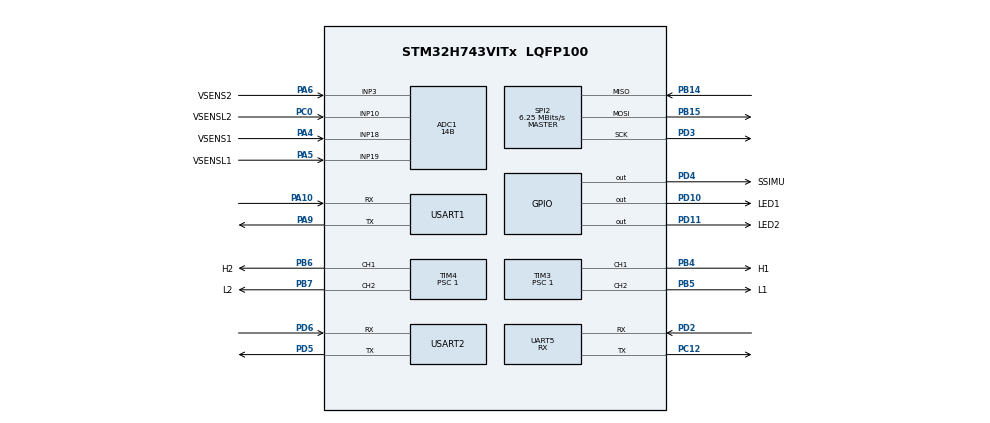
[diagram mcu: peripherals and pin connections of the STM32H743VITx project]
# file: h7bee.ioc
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ADC1.ContinuousConvMode=ENABLE
ADC1.ConversionDataManagement=ADC_CONVERSIONDATA_DR
ADC1.EnableInjectedConversion=ENABLE
ADC1.EnableRegularConversion=DISABLE
ADC1.InjNumberOfConversion=4
ADC1.InjectedChannel-5\#ChannelInjectedConversion=ADC_CHANNEL_3
ADC1.InjectedChannel-6\#ChannelInjectedConversion=ADC_CHANNEL_10
ADC1.InjectedChannel-7\#ChannelInjectedConversion=ADC_CHANNEL_18
ADC1.InjectedChannel-8\#ChannelInjectedConversion=ADC_CHANNEL_19
ADC1.InjectedOffsetNumber-5\#ChannelInjectedConversion=ADC_OFFSET_NONE
ADC1.InjectedOffsetNumber-6\#ChannelInjectedConversion=ADC_OFFSET_NONE
ADC1.InjectedOffsetNumber-7\#ChannelInjectedConversion=ADC_OFFSET_NONE
ADC1.InjectedOffsetNumber-8\#ChannelInjectedConversion=ADC_OFFSET_NONE
ADC1.InjectedRank-5\#ChannelInjectedConversion=1
ADC1.InjectedRank-6\#ChannelInjectedConversion=2
ADC1.InjectedRank-7\#ChannelInjectedConversion=3
ADC1.InjectedRank-8\#ChannelInjectedConversion=4
ADC1.InjectedSamplingTime-5\#ChannelInjectedConversion=ADC_SAMPLETIME_16CYCLES_5
ADC1.InjectedSamplingTime-6\#ChannelInjectedConversion=ADC_SAMPLETIME_1CYCLE_5
ADC1.InjectedSamplingTime-7\#ChannelInjectedConversion=ADC_SAMPLETIME_1CYCLE_5
ADC1.InjectedSamplingTime-8\#ChannelInjectedConversion=ADC_SAMPLETIME_1CYCLE_5
ADC1.Overrun=ADC_OVR_DATA_OVERWRITTEN
ADC1.Resolution=ADC_RESOLUTION_14B
ADC1.injectedQueueMode=DISABLE
ADC1.master=1
CORTEX_M7.CPU_DCache=Enabled
CORTEX_M7.CPU_ICache=Enabled
CORTEX_M7.MPU_Control=MPU_PRIVILEGED_DEFAULT
FREERTOS.MEMORY_ALLOCATION=0
FREERTOS.Tasks01=heartbeatTask,-2,128,startHeartbeatTask,As weak,NULL,Dynamic,NULL,NULL;ImuTask,0,1024,startImuTask,As external,NULL,Dynamic,NULL,NULL;printfTask,-2,1024,startPrintfTask,As external,NULL,Dynamic,NULL,NULL
Mcu.Family=STM32H7
Mcu.Name=STM32H743VITx
Mcu.Package=LQFP100
NVIC.PriorityGroup=NVIC_PRIORITYGROUP_4
NVIC.TIM3_IRQn=true\:2\:0\:true\:false\:true\:false\:true\:true
NVIC.TIM6_DAC_IRQn=true\:1\:0\:true\:false\:true\:false\:true\:true
NVIC.TIM7_IRQn=true\:0\:0\:false\:false\:true\:false\:false\:true
NVIC.TimeBase=TIM7_IRQn
NVIC.TimeBaseIP=TIM7
NVIC.USART1_IRQn=true\:5\:0\:false\:false\:true\:true\:true\:true
PA10.Mode=Asynchronous
PA10.Signal=USART1_RX
PA4.GPIO_Label=VSENS1
PA4.Signal=ADCx_INP18
PA5.GPIO_Label=VSENSL1
PA5.Signal=ADCx_INP19
PA6.GPIO_Label=VSENS2
PA6.Signal=ADCx_INP3
PA9.Mode=Asynchronous
PA9.Signal=USART1_TX
PB14.Mode=Full_Duplex_Master
PB14.Signal=SPI2_MISO
PB15.Mode=Full_Duplex_Master
PB15.Signal=SPI2_MOSI
PB4\ (NJTRST).GPIO_Label=H1
PB4\ (NJTRST).GPIO_Speed=GPIO_SPEED_FREQ_VERY_HIGH
PB4\ (NJTRST).Signal=S_TIM3_CH1
PB5.GPIO_Label=L1
PB5.GPIO_Speed=GPIO_SPEED_FREQ_VERY_HIGH
PB5.Signal=S_TIM3_CH2
PB6.GPIO_Label=H2
PB6.GPIO_Speed=GPIO_SPEED_FREQ_VERY_HIGH
PB6.Signal=S_TIM4_CH1
PB7.GPIO_Label=L2
PB7.GPIO_Speed=GPIO_SPEED_FREQ_VERY_HIGH
PB7.Signal=S_TIM4_CH2
PC0.GPIO_Label=VSENSL2
PC0.Signal=ADCx_INP10
PC12.Mode=Asynchronous
PC12.Signal=UART5_TX
PD10.GPIO_Label=LED1
PD10.GPIO_ModeDefaultOutputPP=GPIO_MODE_OUTPUT_PP
PD10.GPIO_PuPd=GPIO_NOPULL
PD10.GPIO_Speed=GPIO_SPEED_FREQ_LOW
PD10.PinState=GPIO_PIN_SET
PD10.Signal=GPIO_Output
PD11.GPIO_Label=LED2
PD11.GPIO_ModeDefaultOutputPP=GPIO_MODE_OUTPUT_PP
PD11.GPIO_PuPd=GPIO_NOPULL
PD11.GPIO_Speed=GPIO_SPEED_FREQ_LOW
PD11.PinState=GPIO_PIN_SET
PD11.Signal=GPIO_Output
PD2.Mode=Asynchronous
PD2.Signal=UART5_RX
PD3.Mode=Full_Duplex_Master
PD3.Signal=SPI2_SCK
PD4.GPIO_Label=SSIMU
PD4.GPIO_ModeDefaultOutputPP=GPIO_MODE_OUTPUT_PP
PD4.GPIO_PuPd=GPIO_NOPULL
PD4.GPIO_Speed=GPIO_SPEED_FREQ_LOW
PD4.PinState=GPIO_PIN_SET
PD4.Signal=GPIO_Output
PD5.Mode=Asynchronous
PD5.Signal=USART2_TX
PD6.Mode=Asynchronous
PD6.Signal=USART2_RX
PH0-OSC_IN\ (PH0).Mode=HSE-External-Clock-Source
PH0-OSC_IN\ (PH0).Signal=RCC_OSC_IN
PH1-OSC_OUT\ (PH1).Mode=HSE-External-Clock-Source
PH1-OSC_OUT\ (PH1).Signal=RCC_OSC_OUT
ProjectManager.HeapSize=0x200
ProjectManager.StackSize=0x400
ProjectManager.TargetToolchain=Makefile
RCC.ADCFreq_Value=76000000
RCC.APB1Freq_Value=100000000
RCC.APB2Freq_Value=100000000
RCC.APB3Freq_Value=100000000
RCC.APB4Freq_Value=100000000
RCC.CKPERSourceSelection=RCC_CLKPSOURCE_HSE
RCC.CortexFreq_Value=400000000
RCC.D1PPRE=RCC_APB3_DIV2
RCC.D2PPRE1=RCC_APB1_DIV2
RCC.D2PPRE2=RCC_APB2_DIV2
RCC.D3PPRE=RCC_APB4_DIV2
RCC.DIVM1=1
RCC.DIVM2=1
RCC.DIVN1=100
RCC.DIVN2=19
RCC.HCLKFreq_Value=200000000
RCC.HPRE=RCC_HCLK_DIV2
RCC.HSE_VALUE=8000000
RCC.PLL2FRACN=0
RCC.PLL3FRACN=0
RCC.PLLFRACN=0
RCC.PLLSourceVirtual=RCC_PLLSOURCE_HSE
RCC.SYSCLKFreq_VALUE=400000000
RCC.SYSCLKSource=RCC_SYSCLKSOURCE_PLLCLK
RCC.USBFreq_Value=400000000
SH.ADCx_INP10.0=ADC1_INP10,IN10-Single-Ended
SH.ADCx_INP18.0=ADC1_INP18,IN18-Single-Ended
SH.ADCx_INP19.0=ADC1_INP19,IN19-Single-Ended
SH.ADCx_INP3.0=ADC1_INP3,IN3-Single-Ended
SH.S_TIM3_CH1.0=TIM3_CH1,PWM Generation1 CH1
SH.S_TIM3_CH2.0=TIM3_CH2,PWM Generation2 CH2
SH.S_TIM4_CH1.0=TIM4_CH1,PWM Generation1 CH1
SH.S_TIM4_CH2.0=TIM4_CH2,PWM Generation2 CH2
SPI2.BaudRatePrescaler=SPI_BAUDRATEPRESCALER_64
SPI2.CLKPhase=SPI_PHASE_1EDGE
SPI2.CalculateBaudRate=6.25 MBits/s
SPI2.DataSize=SPI_DATASIZE_8BIT
SPI2.Direction=SPI_DIRECTION_2LINES
SPI2.Mode=SPI_MODE_MASTER
SPI2.NSSPMode=SPI_NSS_PULSE_DISABLE
SPI2.VirtualType=VM_MASTER
TIM3.Channel-PWM\ Generation1\ CH1=TIM_CHANNEL_1
TIM3.Channel-PWM\ Generation2\ CH2=TIM_CHANNEL_2
TIM3.Period=9999
TIM3.Prescaler=1
TIM3.Pulse-PWM\ Generation1\ CH1=0
TIM3.Pulse-PWM\ Generation2\ CH2=0
TIM4.Channel-PWM\ Generation1\ CH1=TIM_CHANNEL_1
TIM4.Channel-PWM\ Generation2\ CH2=TIM_CHANNEL_2
TIM4.Period=9999
TIM4.Prescaler=1
TIM6.Period=999
TIM6.Prescaler=199
UART5.Mode=MODE_RX
USART1.VirtualMode-Asynchronous=VM_ASYNC
USART2.DataInvertParam=ADVFEATURE_DATAINV_ENABLE
USART2.RxPinLevelInvertParam=ADVFEATURE_RXINV_DISABLE
USART2.TxPinLevelInvertParam=ADVFEATURE_TXINV_DISABLE
USART2.VirtualMode-Asynchronous=VM_ASYNC
VP_FREERTOS_VS_CMSIS_V1.Mode=CMSIS_V1
VP_SYS_VS_tim7.Mode=TIM7
VP_TIM6_VS_ClockSourceINT.Mode=Enable_Timer
board=custom

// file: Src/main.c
/* USER CODE BEGIN Header */
/**
  ******************************************************************************
  * @file           : main.c
  * @brief          : Main program body
  ******************************************************************************
  * @attention
  *
  * <h2><center>&copy; Copyright (c) 2019 STMicroelectronics.
  * All rights reserved.</center></h2>
  *
  * This software component is licensed by ST under Ultimate Liberty license
  * SLA0044, the "License"; You may not use this file except in compliance with
  * the License. You may obtain a copy of the License at:
  *                             www.st.com/SLA0044
  *
  ******************************************************************************
  */
/* USER CODE END Header */

#include "main.h"
#include "cmsis_os.h"

ADC_HandleTypeDef hadc1;

SPI_HandleTypeDef hspi2;

TIM_HandleTypeDef htim3;
TIM_HandleTypeDef htim4;
TIM_HandleTypeDef htim6;

UART_HandleTypeDef huart5;
UART_HandleTypeDef huart1;
UART_HandleTypeDef huart2;

osThreadId heartbeatTaskHandle;
osThreadId ImuTaskHandle;
osThreadId printfTaskHandle;
/* USER CODE BEGIN PV */
// // adc_results_mem symbol is hardcoded in linker script so don't change it without updating it there
// #define RAM_D2 __attribute__((section(".d2ram")))
// volatile RAM_D2 uint32_t adc_results_mem[4];
/* USER CODE END PV */

void SystemClock_Config(void);
static void MPU_Config(void);
static void MX_GPIO_Init(void);
static void MX_SPI2_Init(void);
static void MX_UART5_Init(void);
static void MX_USART1_UART_Init(void);
static void MX_USART2_UART_Init(void);
static void MX_ADC1_Init(void);
static void MX_TIM3_Init(void);
static void MX_TIM4_Init(void);
static void MX_TIM6_Init(void);
void startHeartbeatTask(void const * argument);
extern void startImuTask(void const * argument);
extern void startPrintfTask(void const * argument);

int main(void)
{

  /* MPU Configuration--------------------------------------------------------*/
  MPU_Config();

  /* Enable I-Cache---------------------------------------------------------*/
  SCB_EnableICache();

  /* Enable D-Cache---------------------------------------------------------*/
  SCB_EnableDCache();

  /* MCU Configuration--------------------------------------------------------*/

  /* Reset of all peripherals, Initializes the Flash interface and the Systick. */
  HAL_Init();

  /* Configure the system clock */
  SystemClock_Config();

  /* Initialize all configured peripherals */
  MX_GPIO_Init();
  MX_SPI2_Init();
  MX_UART5_Init();
  MX_USART1_UART_Init();
  MX_USART2_UART_Init();
  MX_ADC1_Init();
  MX_TIM3_Init();
  MX_TIM4_Init();
  MX_TIM6_Init();
  /* USER CODE BEGIN 2 */

  // Start all the things that need to be started

  // System clock
  HAL_TIM_Base_Start(&htim6);
  HAL_TIM_Base_Start_IT(&htim6);

  // Drive PWM
  HAL_TIM_Base_Start(&htim3);
  HAL_TIM_PWM_Start(&htim3, TIM_CHANNEL_1);
  HAL_TIM_PWM_Start(&htim3, TIM_CHANNEL_2);
  HAL_TIM_Base_Start(&htim4);
  HAL_TIM_PWM_Start(&htim4, TIM_CHANNEL_1);
  HAL_TIM_PWM_Start(&htim4, TIM_CHANNEL_2);

  // ADC
  // for (int i = 0; i < 4; ++i)
  //   adc_results_mem[i] = 0;
  // HAL_ADC_Start_DMA(&hadc1, (uint32_t *)adc_results_mem, 4); // returns HAL_OK
  // HAL_ADC_Start(&hadc1);
  HAL_ADCEx_InjectedStart(&hadc1);

  // Flap task timebase (timer interrupt)
  HAL_TIM_Base_Start_IT(&htim3);

  /* USER CODE END 2 */

  /* Create the thread(s) */
  /* definition and creation of heartbeatTask */
  osThreadDef(heartbeatTask, startHeartbeatTask, osPriorityLow, 0, 128);
  heartbeatTaskHandle = osThreadCreate(osThread(heartbeatTask), NULL);

  /* definition and creation of ImuTask */
  osThreadDef(ImuTask, startImuTask, osPriorityNormal, 0, 1024);
  ImuTaskHandle = osThreadCreate(osThread(ImuTask), NULL);

  /* definition and creation of printfTask */
  osThreadDef(printfTask, startPrintfTask, osPriorityLow, 0, 1024);
  printfTaskHandle = osThreadCreate(osThread(printfTask), NULL);

  /* Start scheduler */
  osKernelStart();

  /* We should never get here as control is now taken by the scheduler */

  /* Infinite loop */
  while (1)
  {

  }
}

void SystemClock_Config(void)
{
  RCC_OscInitTypeDef RCC_OscInitStruct = {0};
  RCC_ClkInitTypeDef RCC_ClkInitStruct = {0};
  RCC_PeriphCLKInitTypeDef PeriphClkInitStruct = {0};

  /** Supply configuration update enable
  */
  HAL_PWREx_ConfigSupply(PWR_LDO_SUPPLY);
  /** Configure the main internal regulator output voltage
  */
  __HAL_PWR_VOLTAGESCALING_CONFIG(PWR_REGULATOR_VOLTAGE_SCALE1);

  while(!__HAL_PWR_GET_FLAG(PWR_FLAG_VOSRDY)) {}
  /** Macro to configure the PLL clock source
  */
  __HAL_RCC_PLL_PLLSOURCE_CONFIG(RCC_PLLSOURCE_HSE);
  /** Initializes the CPU, AHB and APB busses clocks
  */
  RCC_OscInitStruct.OscillatorType = RCC_OSCILLATORTYPE_HSE;
  RCC_OscInitStruct.HSEState = RCC_HSE_BYPASS;
  RCC_OscInitStruct.PLL.PLLState = RCC_PLL_ON;
  RCC_OscInitStruct.PLL.PLLSource = RCC_PLLSOURCE_HSE;
  RCC_OscInitStruct.PLL.PLLM = 1;
  RCC_OscInitStruct.PLL.PLLN = 100;
  RCC_OscInitStruct.PLL.PLLP = 2;
  RCC_OscInitStruct.PLL.PLLQ = 2;
  RCC_OscInitStruct.PLL.PLLR = 2;
  RCC_OscInitStruct.PLL.PLLRGE = RCC_PLL1VCIRANGE_3;
  RCC_OscInitStruct.PLL.PLLVCOSEL = RCC_PLL1VCOWIDE;
  RCC_OscInitStruct.PLL.PLLFRACN = 0;
  if (HAL_RCC_OscConfig(&RCC_OscInitStruct) != HAL_OK)
  {
    Error_Handler();
  }
  /** Initializes the CPU, AHB and APB busses clocks
  */
  RCC_ClkInitStruct.ClockType = RCC_CLOCKTYPE_HCLK|RCC_CLOCKTYPE_SYSCLK
                              |RCC_CLOCKTYPE_PCLK1|RCC_CLOCKTYPE_PCLK2
                              |RCC_CLOCKTYPE_D3PCLK1|RCC_CLOCKTYPE_D1PCLK1;
  RCC_ClkInitStruct.SYSCLKSource = RCC_SYSCLKSOURCE_PLLCLK;
  RCC_ClkInitStruct.SYSCLKDivider = RCC_SYSCLK_DIV1;
  RCC_ClkInitStruct.AHBCLKDivider = RCC_HCLK_DIV2;
  RCC_ClkInitStruct.APB3CLKDivider = RCC_APB3_DIV2;
  RCC_ClkInitStruct.APB1CLKDivider = RCC_APB1_DIV2;
  RCC_ClkInitStruct.APB2CLKDivider = RCC_APB2_DIV2;
  RCC_ClkInitStruct.APB4CLKDivider = RCC_APB4_DIV2;

  if (HAL_RCC_ClockConfig(&RCC_ClkInitStruct, FLASH_LATENCY_2) != HAL_OK)
  {
    Error_Handler();
  }
  PeriphClkInitStruct.PeriphClockSelection = RCC_PERIPHCLK_USART2|RCC_PERIPHCLK_USART1
                              |RCC_PERIPHCLK_UART5|RCC_PERIPHCLK_SPI2
                              |RCC_PERIPHCLK_ADC;
  PeriphClkInitStruct.PLL2.PLL2M = 1;
  PeriphClkInitStruct.PLL2.PLL2N = 19;
  PeriphClkInitStruct.PLL2.PLL2P = 2;
  PeriphClkInitStruct.PLL2.PLL2Q = 2;
  PeriphClkInitStruct.PLL2.PLL2R = 2;
  PeriphClkInitStruct.PLL2.PLL2RGE = RCC_PLL2VCIRANGE_3;
  PeriphClkInitStruct.PLL2.PLL2VCOSEL = RCC_PLL2VCOMEDIUM;
  PeriphClkInitStruct.PLL2.PLL2FRACN = 0;
  PeriphClkInitStruct.Spi123ClockSelection = RCC_SPI123CLKSOURCE_PLL;
  PeriphClkInitStruct.Usart234578ClockSelection = RCC_USART234578CLKSOURCE_D2PCLK1;
  PeriphClkInitStruct.Usart16ClockSelection = RCC_USART16CLKSOURCE_D2PCLK2;
  PeriphClkInitStruct.AdcClockSelection = RCC_ADCCLKSOURCE_PLL2;
  if (HAL_RCCEx_PeriphCLKConfig(&PeriphClkInitStruct) != HAL_OK)
  {
    Error_Handler();
  }
}

static void MX_ADC1_Init(void)
{

  ADC_MultiModeTypeDef multimode = {0};
  ADC_InjectionConfTypeDef sConfigInjected = {0};

  /** Common config
  */
  hadc1.Instance = ADC1;
  hadc1.Init.ClockPrescaler = ADC_CLOCK_ASYNC_DIV4;
  hadc1.Init.Resolution = ADC_RESOLUTION_14B;
  hadc1.Init.ScanConvMode = ADC_SCAN_ENABLE;
  hadc1.Init.EOCSelection = ADC_EOC_SINGLE_CONV;
  hadc1.Init.LowPowerAutoWait = DISABLE;
  hadc1.Init.ContinuousConvMode = ENABLE;
  hadc1.Init.NbrOfConversion = 1;
  hadc1.Init.DiscontinuousConvMode = DISABLE;
  hadc1.Init.ConversionDataManagement = ADC_CONVERSIONDATA_DR;
  hadc1.Init.Overrun = ADC_OVR_DATA_OVERWRITTEN;
  hadc1.Init.OversamplingMode = DISABLE;
  if (HAL_ADC_Init(&hadc1) != HAL_OK)
  {
    Error_Handler();
  }
  /** Configure the ADC multi-mode
  */
  multimode.Mode = ADC_MODE_INDEPENDENT;
  if (HAL_ADCEx_MultiModeConfigChannel(&hadc1, &multimode) != HAL_OK)
  {
    Error_Handler();
  }
  /** Disable Injected Queue
  */
  HAL_ADCEx_DisableInjectedQueue(&hadc1);
  /** Configure Injected Channel
  */
  sConfigInjected.InjectedChannel = ADC_CHANNEL_3;
  sConfigInjected.InjectedRank = ADC_INJECTED_RANK_1;
  sConfigInjected.InjectedSamplingTime = ADC_SAMPLETIME_16CYCLES_5;
  sConfigInjected.InjectedSingleDiff = ADC_SINGLE_ENDED;
  sConfigInjected.InjectedOffsetNumber = ADC_OFFSET_NONE;
  sConfigInjected.InjectedOffset = 0;
  sConfigInjected.InjectedLeftBitShift = ADC_LEFTBITSHIFT_NONE;
  sConfigInjected.InjectedNbrOfConversion = 4;
  sConfigInjected.InjectedDiscontinuousConvMode = DISABLE;
  sConfigInjected.AutoInjectedConv = DISABLE;
  sConfigInjected.QueueInjectedContext = DISABLE;
  sConfigInjected.ExternalTrigInjecConv = ADC_INJECTED_SOFTWARE_START;
  sConfigInjected.ExternalTrigInjecConvEdge = ADC_EXTERNALTRIGINJECCONV_EDGE_NONE;
  sConfigInjected.InjecOversamplingMode = DISABLE;
  if (HAL_ADCEx_InjectedConfigChannel(&hadc1, &sConfigInjected) != HAL_OK)
  {
    Error_Handler();
  }
  /** Configure Injected Channel
  */
  sConfigInjected.InjectedChannel = ADC_CHANNEL_10;
  sConfigInjected.InjectedRank = ADC_INJECTED_RANK_2;
  sConfigInjected.InjectedSamplingTime = ADC_SAMPLETIME_1CYCLE_5;
  if (HAL_ADCEx_InjectedConfigChannel(&hadc1, &sConfigInjected) != HAL_OK)
  {
    Error_Handler();
  }
  /** Configure Injected Channel
  */
  sConfigInjected.InjectedChannel = ADC_CHANNEL_18;
  sConfigInjected.InjectedRank = ADC_INJECTED_RANK_3;
  if (HAL_ADCEx_InjectedConfigChannel(&hadc1, &sConfigInjected) != HAL_OK)
  {
    Error_Handler();
  }
  /** Configure Injected Channel
  */
  sConfigInjected.InjectedChannel = ADC_CHANNEL_19;
  sConfigInjected.InjectedRank = ADC_INJECTED_RANK_4;
  if (HAL_ADCEx_InjectedConfigChannel(&hadc1, &sConfigInjected) != HAL_OK)
  {
    Error_Handler();
  }

}

static void MX_SPI2_Init(void)
{

  /* SPI2 parameter configuration*/
  hspi2.Instance = SPI2;
  hspi2.Init.Mode = SPI_MODE_MASTER;
  hspi2.Init.Direction = SPI_DIRECTION_2LINES;
  hspi2.Init.DataSize = SPI_DATASIZE_8BIT;
  hspi2.Init.CLKPolarity = SPI_POLARITY_LOW;
  hspi2.Init.CLKPhase = SPI_PHASE_1EDGE;
  hspi2.Init.NSS = SPI_NSS_SOFT;
  hspi2.Init.BaudRatePrescaler = SPI_BAUDRATEPRESCALER_64;
  hspi2.Init.FirstBit = SPI_FIRSTBIT_MSB;
  hspi2.Init.TIMode = SPI_TIMODE_DISABLE;
  hspi2.Init.CRCCalculation = SPI_CRCCALCULATION_DISABLE;
  hspi2.Init.CRCPolynomial = 0x0;
  hspi2.Init.NSSPMode = SPI_NSS_PULSE_DISABLE;
  hspi2.Init.NSSPolarity = SPI_NSS_POLARITY_LOW;
  hspi2.Init.FifoThreshold = SPI_FIFO_THRESHOLD_01DATA;
  hspi2.Init.TxCRCInitializationPattern = SPI_CRC_INITIALIZATION_ALL_ZERO_PATTERN;
  hspi2.Init.RxCRCInitializationPattern = SPI_CRC_INITIALIZATION_ALL_ZERO_PATTERN;
  hspi2.Init.MasterSSIdleness = SPI_MASTER_SS_IDLENESS_00CYCLE;
  hspi2.Init.MasterInterDataIdleness = SPI_MASTER_INTERDATA_IDLENESS_00CYCLE;
  hspi2.Init.MasterReceiverAutoSusp = SPI_MASTER_RX_AUTOSUSP_DISABLE;
  hspi2.Init.MasterKeepIOState = SPI_MASTER_KEEP_IO_STATE_DISABLE;
  hspi2.Init.IOSwap = SPI_IO_SWAP_DISABLE;
  if (HAL_SPI_Init(&hspi2) != HAL_OK)
  {
    Error_Handler();
  }

}

static void MX_TIM3_Init(void)
{

  TIM_MasterConfigTypeDef sMasterConfig = {0};
  TIM_OC_InitTypeDef sConfigOC = {0};

  htim3.Instance = TIM3;
  htim3.Init.Prescaler = 1;
  htim3.Init.CounterMode = TIM_COUNTERMODE_UP;
  htim3.Init.Period = 9999;
  htim3.Init.ClockDivision = TIM_CLOCKDIVISION_DIV1;
  htim3.Init.AutoReloadPreload = TIM_AUTORELOAD_PRELOAD_DISABLE;
  if (HAL_TIM_PWM_Init(&htim3) != HAL_OK)
  {
    Error_Handler();
  }
  sMasterConfig.MasterOutputTrigger = TIM_TRGO_RESET;
  sMasterConfig.MasterSlaveMode = TIM_MASTERSLAVEMODE_DISABLE;
  if (HAL_TIMEx_MasterConfigSynchronization(&htim3, &sMasterConfig) != HAL_OK)
  {
    Error_Handler();
  }
  sConfigOC.OCMode = TIM_OCMODE_PWM1;
  sConfigOC.Pulse = 0;
  sConfigOC.OCPolarity = TIM_OCPOLARITY_HIGH;
  sConfigOC.OCFastMode = TIM_OCFAST_DISABLE;
  if (HAL_TIM_PWM_ConfigChannel(&htim3, &sConfigOC, TIM_CHANNEL_1) != HAL_OK)
  {
    Error_Handler();
  }
  if (HAL_TIM_PWM_ConfigChannel(&htim3, &sConfigOC, TIM_CHANNEL_2) != HAL_OK)
  {
    Error_Handler();
  }
  HAL_TIM_MspPostInit(&htim3);

}

static void MX_TIM4_Init(void)
{

  TIM_MasterConfigTypeDef sMasterConfig = {0};
  TIM_OC_InitTypeDef sConfigOC = {0};

  htim4.Instance = TIM4;
  htim4.Init.Prescaler = 1;
  htim4.Init.CounterMode = TIM_COUNTERMODE_UP;
  htim4.Init.Period = 9999;
  htim4.Init.ClockDivision = TIM_CLOCKDIVISION_DIV1;
  htim4.Init.AutoReloadPreload = TIM_AUTORELOAD_PRELOAD_DISABLE;
  if (HAL_TIM_PWM_Init(&htim4) != HAL_OK)
  {
    Error_Handler();
  }
  sMasterConfig.MasterOutputTrigger = TIM_TRGO_RESET;
  sMasterConfig.MasterSlaveMode = TIM_MASTERSLAVEMODE_DISABLE;
  if (HAL_TIMEx_MasterConfigSynchronization(&htim4, &sMasterConfig) != HAL_OK)
  {
    Error_Handler();
  }
  sConfigOC.OCMode = TIM_OCMODE_PWM1;
  sConfigOC.Pulse = 0;
  sConfigOC.OCPolarity = TIM_OCPOLARITY_HIGH;
  sConfigOC.OCFastMode = TIM_OCFAST_DISABLE;
  if (HAL_TIM_PWM_ConfigChannel(&htim4, &sConfigOC, TIM_CHANNEL_1) != HAL_OK)
  {
    Error_Handler();
  }
  if (HAL_TIM_PWM_ConfigChannel(&htim4, &sConfigOC, TIM_CHANNEL_2) != HAL_OK)
  {
    Error_Handler();
  }
  HAL_TIM_MspPostInit(&htim4);

}

static void MX_TIM6_Init(void)
{

  TIM_MasterConfigTypeDef sMasterConfig = {0};

  htim6.Instance = TIM6;
  htim6.Init.Prescaler = 199;
  htim6.Init.CounterMode = TIM_COUNTERMODE_UP;
  htim6.Init.Period = 999;
  htim6.Init.AutoReloadPreload = TIM_AUTORELOAD_PRELOAD_DISABLE;
  if (HAL_TIM_Base_Init(&htim6) != HAL_OK)
  {
    Error_Handler();
  }
  sMasterConfig.MasterOutputTrigger = TIM_TRGO_RESET;
  sMasterConfig.MasterSlaveMode = TIM_MASTERSLAVEMODE_DISABLE;
  if (HAL_TIMEx_MasterConfigSynchronization(&htim6, &sMasterConfig) != HAL_OK)
  {
    Error_Handler();
  }

}

static void MX_UART5_Init(void)
{

  huart5.Instance = UART5;
  huart5.Init.BaudRate = 115200;
  huart5.Init.WordLength = UART_WORDLENGTH_8B;
  huart5.Init.StopBits = UART_STOPBITS_1;
  huart5.Init.Parity = UART_PARITY_NONE;
  huart5.Init.Mode = UART_MODE_RX;
  huart5.Init.HwFlowCtl = UART_HWCONTROL_NONE;
  huart5.Init.OverSampling = UART_OVERSAMPLING_16;
  huart5.Init.OneBitSampling = UART_ONE_BIT_SAMPLE_DISABLE;
  huart5.Init.ClockPrescaler = UART_PRESCALER_DIV1;
  huart5.AdvancedInit.AdvFeatureInit = UART_ADVFEATURE_NO_INIT;
  if (HAL_UART_Init(&huart5) != HAL_OK)
  {
    Error_Handler();
  }
  if (HAL_UARTEx_SetTxFifoThreshold(&huart5, UART_TXFIFO_THRESHOLD_1_8) != HAL_OK)
  {
    Error_Handler();
  }
  if (HAL_UARTEx_SetRxFifoThreshold(&huart5, UART_RXFIFO_THRESHOLD_1_8) != HAL_OK)
  {
    Error_Handler();
  }
  if (HAL_UARTEx_DisableFifoMode(&huart5) != HAL_OK)
  {
    Error_Handler();
  }

}

static void MX_USART1_UART_Init(void)
{

  huart1.Instance = USART1;
  huart1.Init.BaudRate = 115200;
  huart1.Init.WordLength = UART_WORDLENGTH_8B;
  huart1.Init.StopBits = UART_STOPBITS_1;
  huart1.Init.Parity = UART_PARITY_NONE;
  huart1.Init.Mode = UART_MODE_TX_RX;
  huart1.Init.HwFlowCtl = UART_HWCONTROL_NONE;
  huart1.Init.OverSampling = UART_OVERSAMPLING_16;
  huart1.Init.OneBitSampling = UART_ONE_BIT_SAMPLE_DISABLE;
  huart1.Init.ClockPrescaler = UART_PRESCALER_DIV1;
  huart1.AdvancedInit.AdvFeatureInit = UART_ADVFEATURE_NO_INIT;
  if (HAL_UART_Init(&huart1) != HAL_OK)
  {
    Error_Handler();
  }
  if (HAL_UARTEx_SetTxFifoThreshold(&huart1, UART_TXFIFO_THRESHOLD_1_8) != HAL_OK)
  {
    Error_Handler();
  }
  if (HAL_UARTEx_SetRxFifoThreshold(&huart1, UART_RXFIFO_THRESHOLD_1_8) != HAL_OK)
  {
    Error_Handler();
  }
  if (HAL_UARTEx_DisableFifoMode(&huart1) != HAL_OK)
  {
    Error_Handler();
  }

}

static void MX_USART2_UART_Init(void)
{

  huart2.Instance = USART2;
  huart2.Init.BaudRate = 115200;
  huart2.Init.WordLength = UART_WORDLENGTH_8B;
  huart2.Init.StopBits = UART_STOPBITS_1;
  huart2.Init.Parity = UART_PARITY_NONE;
  huart2.Init.Mode = UART_MODE_TX_RX;
  huart2.Init.HwFlowCtl = UART_HWCONTROL_NONE;
  huart2.Init.OverSampling = UART_OVERSAMPLING_16;
  huart2.Init.OneBitSampling = UART_ONE_BIT_SAMPLE_DISABLE;
  huart2.Init.ClockPrescaler = UART_PRESCALER_DIV1;
  huart2.AdvancedInit.AdvFeatureInit = UART_ADVFEATURE_DATAINVERT_INIT;
  huart2.AdvancedInit.DataInvert = UART_ADVFEATURE_DATAINV_ENABLE;
  if (HAL_UART_Init(&huart2) != HAL_OK)
  {
    Error_Handler();
  }
  if (HAL_UARTEx_SetTxFifoThreshold(&huart2, UART_TXFIFO_THRESHOLD_1_8) != HAL_OK)
  {
    Error_Handler();
  }
  if (HAL_UARTEx_SetRxFifoThreshold(&huart2, UART_RXFIFO_THRESHOLD_1_8) != HAL_OK)
  {
    Error_Handler();
  }
  if (HAL_UARTEx_DisableFifoMode(&huart2) != HAL_OK)
  {
    Error_Handler();
  }

}

static void MX_GPIO_Init(void)
{
  GPIO_InitTypeDef GPIO_InitStruct = {0};

  /* GPIO Ports Clock Enable */
  __HAL_RCC_GPIOH_CLK_ENABLE();
  __HAL_RCC_GPIOC_CLK_ENABLE();
  __HAL_RCC_GPIOA_CLK_ENABLE();
  __HAL_RCC_GPIOB_CLK_ENABLE();
  __HAL_RCC_GPIOD_CLK_ENABLE();

  /*Configure GPIO pin Output Level */
  HAL_GPIO_WritePin(GPIOD, LED1_Pin|LED2_Pin|SSIMU_Pin, GPIO_PIN_SET);

  /*Configure GPIO pins : LED1_Pin LED2_Pin SSIMU_Pin */
  GPIO_InitStruct.Pin = LED1_Pin|LED2_Pin|SSIMU_Pin;
  GPIO_InitStruct.Mode = GPIO_MODE_OUTPUT_PP;
  GPIO_InitStruct.Pull = GPIO_NOPULL;
  GPIO_InitStruct.Speed = GPIO_SPEED_FREQ_LOW;
  HAL_GPIO_Init(GPIOD, &GPIO_InitStruct);

}

__weak void startHeartbeatTask(void const * argument)
{

  /* USER CODE BEGIN 5 */
  /* Infinite loop */
  for(;;)
  {
    HAL_GPIO_TogglePin(LED2_GPIO_Port, LED2_Pin);
    osDelay(100);
  }
  /* USER CODE END 5 */
}

/* MPU Configuration */

void MPU_Config(void)
{

  /* Disables the MPU */
  HAL_MPU_Disable();
  /* Enables the MPU */
  HAL_MPU_Enable(MPU_PRIVILEGED_DEFAULT);

}
void HAL_TIM_PeriodElapsedCallback(TIM_HandleTypeDef *htim)
{
  if (htim->Instance == TIM7) {
    HAL_IncTick();
  }
}

void Error_Handler(void)
{
}

/************************ (C) COPYRIGHT STMicroelectronics *****END OF FILE****/
